# STM32MP21_CM33 register map
File version: 0.4
CPU: CM33 r0p1, little endian, MPU, FPU, vendor SysTick, 8 interrupt priority bits
Registers are 32-bit, read-write, reset 0x0 unless marked. A register's access mark holds for its fields unless they carry their own. Offsets are from the block's base; [hi:lo] are bit positions; {n}, {i} and the like mark numbered series; 'fields as' and 'values as' point back to an identical list.

## ETH1 (part 2 of 2) — ETH address block description
Base 0x482C0000
Same registers: ETH2 0x482D0000, ETH1_S 0x582C0000, ETH2_S 0x582D0000
0x7B8 ETH_RX_256TO511OCTETS_PACKETS_GOOD_BAD ro — Rx 256 to 511 octets packets good bad register
  [31:0] RX256_511OCTGB — Rx 256-511 Octets Packets Good Bad
0x7BC ETH_RX_512TO1023OCTETS_PACKETS_GOOD_BAD ro — Rx 512 to 1023 octets packets good bad register
  [31:0] RX512_1023OCTGB — Rx 512-1023 Octets Packets Good Bad
0x7C0 ETH_RX_1024TOMAXOCTETS_PACKETS_GOOD_BAD ro — Rx 1024 to max octets packets good bad register
  [31:0] RX1024_MAXOCTGB — Rx 1024-Max Octets Good Bad
0x7C4 ETH_RX_UNICAST_PACKETS_GOOD ro — Rx unicast packets good register
  [31:0] RXUCASTG — Rx Unicast Packets Good
0x7C8 ETH_RX_LENGTH_ERROR_PACKETS ro — Rx length error packets register
  [31:0] RXLENERR — Rx Length Error Packets
0x7CC ETH_RX_OUT_OF_RANGE_PACKETS ro — Rx out of range type packets register
  [31:0] RXOUTOFRNG — Rx Out of Range Type Packet
0x7D0 ETH_RX_PAUSE_PACKETS ro — Rx pause packets register
  [31:0] RXPAUSEPKT — Rx Pause Packets
0x7D4 ETH_RX_FIFO_OVERFLOW_PACKETS ro — Rx FIFO overflow packets register
  [31:0] RXFIFOOVFL — Rx FIFO Overflow Packets
0x7D8 ETH_RX_VLAN_PACKETS_GOOD_BAD ro — Rx VLAN packets good bad register
  [31:0] RXVLANPKTGB — Rx VLAN Packets Good Bad
0x7DC ETH_RX_WATCHDOG_ERROR_PACKETS ro — Rx watchdog error packets register
  [31:0] RXWDGERR — Rx Watchdog Error Packets
0x7E0 ETH_RX_RECEIVE_ERROR ro — Rx receive error register
  [31:0] RXRCVERR — Rx Receive Error Packets
0x7E4 ETH_RX_CONTROL_PACKETS_GOOD ro — Rx control packets good register
  [31:0] RXCTRLG — Rx Control Packets Good
0x7EC ETH_TX_LPI_USEC_CNTR ro — Tx LPI microsecond timer register
  [31:0] TXLPIUSC — Tx LPI Microseconds Counter
0x7F0 ETH_TX_LPI_TRAN_CNTR ro — Tx LPI transition counter register
  [31:0] TXLPITRC — Tx LPI Transition counter
0x7F4 ETH_RX_LPI_USEC_CNTR ro — Rx LPI microsecond counter register
  [31:0] RXLPIUSC — Rx LPI Microseconds Counter
0x7F8 ETH_RX_LPI_TRAN_CNTR ro — Rx LPI transition counter register
  [31:0] RXLPITRC — Rx LPI Transition counter
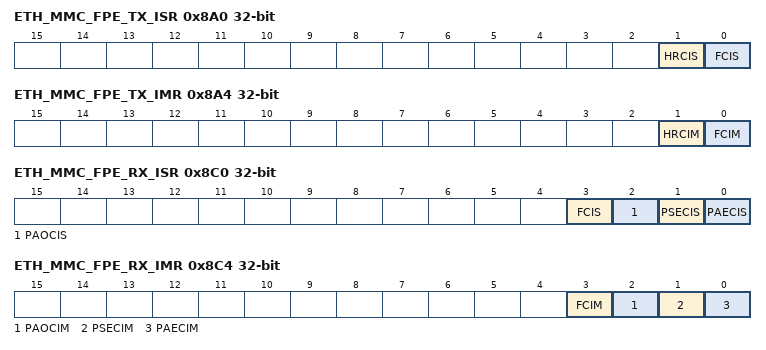
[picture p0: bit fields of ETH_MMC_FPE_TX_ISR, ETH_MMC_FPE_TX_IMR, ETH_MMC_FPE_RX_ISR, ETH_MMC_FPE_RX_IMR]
0x8A0 ETH_MMC_FPE_TX_ISR — MMC FPE Tx interrupt status register
  [1] HRCIS — MMC Tx Hold Request Counter Interrupt Status
  [0] FCIS — MMC Tx FPE Fragment Counter Interrupt status
0x8A4 ETH_MMC_FPE_TX_IMR — MMC FPE Tx interrupt mask register
  [1] HRCIM — MMC Transmit Hold Request Counter Interrupt Mask
  [0] FCIM — MMC Transmit Fragment Counter Interrupt Mask
0x8A8 ETH_MMC_FPE_TX_FCR ro — MMC FPE Tx fragment counter register
  [31:0] TXFFC — Tx FPE Fragment counter
0x8AC ETH_MMC_TX_HRCR ro — MMC Tx hold request counter register
  [31:0] TXHRC — Tx Hold Request Counter
0x8C0 ETH_MMC_FPE_RX_ISR ro — MMC FPE Rx interrupt status register
  [3] FCIS — MMC Rx FPE Fragment Counter Interrupt Status
  [2] PAOCIS — MMC Rx Packet Assembly OK Counter Interrupt Status
  [1] PSECIS — MMC Rx Packet SMD Error Counter Interrupt Status
  [0] PAECIS — MMC Rx Packet Assembly Error Counter Interrupt Status
0x8C4 ETH_MMC_FPE_RX_IMR — MMC FPE Rx interrupt mask register
  [3] FCIM — MMC Rx FPE Fragment Counter Interrupt Mask
  [2] PAOCIM — MMC Rx Packet Assembly OK Counter Interrupt Mask
  [1] PSECIM — MMC Rx Packet SMD Error Counter Interrupt Mask
  [0] PAECIM — MMC Rx Packet Assembly Error Counter Interrupt Mask
0x8C8 ETH_RX_PACKET_ASM_ERR ro — MMC Rx packet assembly error register
  [31:0] PAEC — Rx Packet Assembly Error Counter
0x8CC ETH_RX_PACKET_SMD_ERR ro — MMC Rx packet SMD error register
  [31:0] PSEC — Rx Packet SMD Error Counter
0x8D0 ETH_RX_PACKET_ASM_OKR ro — MMC Rx packet assembly OK register
  [31:0] PAOC — Rx Packet Assembly OK Counter
0x8D4 ETH_RX_FPE_FRAG_CR ro — MMC Rx FPE fragments counter register
  [31:0] FFC — Rx FPE Fragment Counter
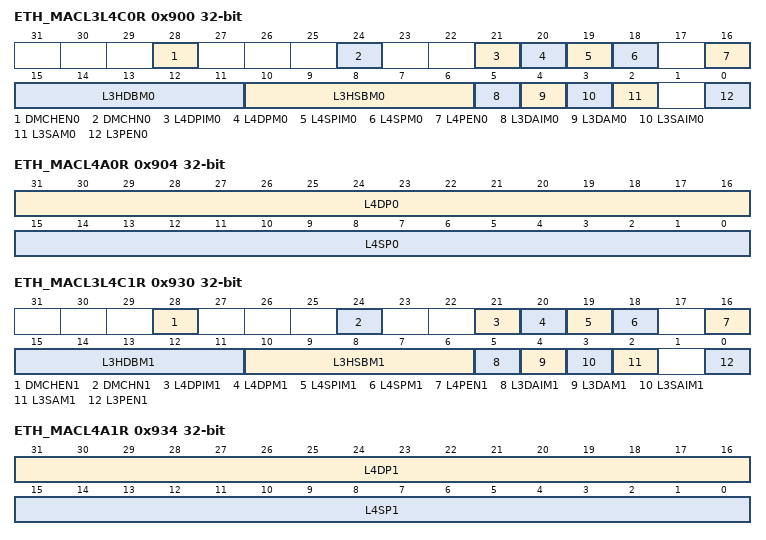
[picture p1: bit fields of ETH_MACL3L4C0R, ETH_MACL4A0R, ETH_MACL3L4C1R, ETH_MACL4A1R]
0x900 ETH_MACL3L4C0R — L3 and L4 control 0 register
  [28] DMCHEN0 — DMA Channel Select Enable
  [24] DMCHN0 — DMA Channel Number
    0=DMA channel 0; 1=DMA channel 1
  [21] L4DPIM0 — Layer 4 Destination Port Inverse Match Enable
  [20] L4DPM0 — Layer 4 Destination Port Match Enable
  [19] L4SPIM0 — Layer 4 Source Port Inverse Match Enable
  [18] L4SPM0 — Layer 4 Source Port Match Enable
  [16] L4PEN0 — Layer 4 Protocol Enable
  [15:11] L3HDBM0 — Layer 3 IP DA higher bits match
    0=B_0x0_IPV4_PACKETS (No bits are masked.); 1=B_0x1_IPV4_PACKETS (LSb[0] is masked)
  [10:6] L3HSBM0 — Layer 3 IP SA higher bits match
    values as L3HDBM0
  [5] L3DAIM0 — Layer 3 IP DA Inverse Match Enable
  [4] L3DAM0 — Layer 3 IP DA Match Enable
  [3] L3SAIM0 — Layer 3 IP SA Inverse Match Enable
  [2] L3SAM0 — Layer 3 IP SA Match Enable
  [0] L3PEN0 — Layer 3 Protocol Enable
0x904 ETH_MACL4A0R — Layer4 Address filter 0 register
  [31:16] L4DP0 — Layer 4 Destination Port Number Field
  [15:0] L4SP0 — Layer 4 Source Port Number Field
0x910 ETH_MACL3A00R — Layer3 Address 0 filter 0 register
  [31:0] L3A00 — Layer 3 Address 0 Field
0x914 ETH_MACL3A10R — Layer3 Address 1 filter 0 register
  [31:0] L3A10 — Layer 3 Address 1 Field
0x918 ETH_MACL3A20R — Layer3 Address 2 filter 0 register
  [31:0] L3A20 — Layer 3 Address 2 Field
0x91C ETH_MACL3A30R — Layer3 Address 3 filter 0 register
  [31:0] L3A30 — Layer 3 Address 3 Field
0x930 ETH_MACL3L4C1R — L3 and L4 control 1 register
  [28] DMCHEN1 — DMA Channel Select Enable
  [24] DMCHN1 — DMA Channel Number
  [21] L4DPIM1 — Layer 4 Destination Port Inverse Match Enable
  [20] L4DPM1 — Layer 4 Destination Port Match Enable
  [19] L4SPIM1 — Layer 4 Source Port Inverse Match Enable
  [18] L4SPM1 — Layer 4 Source Port Match Enable
  [16] L4PEN1 — Layer 4 Protocol Enable
  [15:11] L3HDBM1 — Layer 3 IP DA higher bits match
    values as ETH_MACL3L4C0R.L3HDBM0
  [10:6] L3HSBM1 — Layer 3 IP SA Higher Bits Match
    values as ETH_MACL3L4C0R.L3HDBM0
  [5] L3DAIM1 — Layer 3 IP DA Inverse Match Enable
  [4] L3DAM1 — Layer 3 IP DA Match Enable
  [3] L3SAIM1 — Layer 3 IP SA Inverse Match Enable
  [2] L3SAM1 — Layer 3 IP SA Match Enable
  [0] L3PEN1 — Layer 3 Protocol Enable
0x934 ETH_MACL4A1R — Layer 4 address filter 1 register
  [31:16] L4DP1 — Layer 4 Destination Port Number Field
  [15:0] L4SP1 — Layer 4 Source Port Number Field
0x940 ETH_MACL3A01R — Layer3 address 0 filter 1 Register
  [31:0] L3A01 — Layer 3 Address 0 Field
0x944 ETH_MACL3A11R — Layer3 address 1 filter 1 register
  [31:0] L3A11 — Layer 3 Address 1 Field
0x948 ETH_MACL3A21R — Layer3 address 2 filter 1 Register
  [31:0] L3A21 — Layer 3 Address 2 Field
0x94C ETH_MACL3A31R — Layer3 address 3 filter 1 register
  [31:0] L3A31 — Layer 3 Address 3 Field
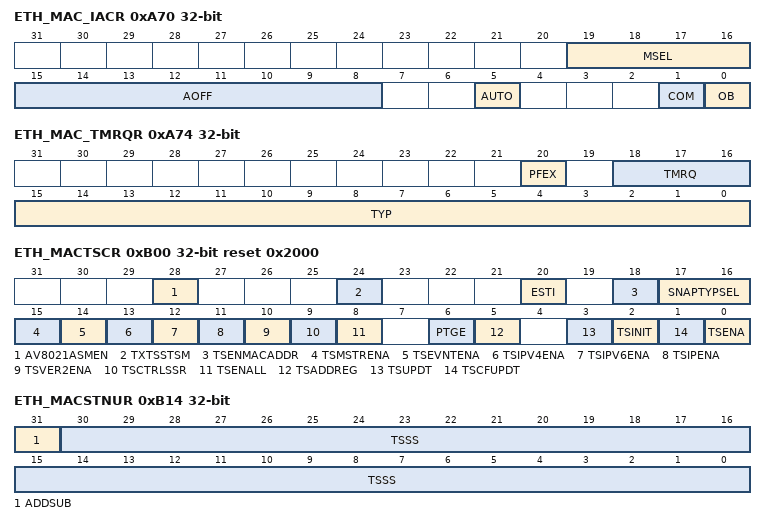
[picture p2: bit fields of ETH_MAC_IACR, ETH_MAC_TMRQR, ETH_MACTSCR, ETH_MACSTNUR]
0xA70 ETH_MAC_IACR — MAC Indirect Access Control register
  [19:16] MSEL — Mode Select
    0=Typ_RXQ_ (Type-based RXQ mapping)
  [15:8] AOFF — Address Offset
    0=IndReg0 (Indirect register 0); 1=IndReg1 (Indirect register 1); 7=IndReg7 (Indirect register 7)
  [5] AUTO — Auto-increment
    1=AOFF is incremented by 1; 0=AOFF is not automatically incremented
  [1] COM — Command type
    1=Indicates a read operation; 0=Indicates a write operation
  [0] OB — Operation Busy.
0xA74 ETH_MAC_TMRQR — MAC type-based Rx Queue mapping register
  [20] PFEX — Preemption or Express Packet
    0=Express packet; 1=Preemption packet
  [18:16] TMRQ — Type Match Rx Queue Number
  [15:0] TYP — Type field Value
0xB00 ETH_MACTSCR reset 0x2000 — Timestamp control Register
  [28] AV8021ASMEN — AV 802.
  [24] TXTSSTSM — Transmit Timestamp Status Mode
  [20] ESTI — External System Time Input
  [18] TSENMACADDR — Enable MAC Address for PTP Packet Filtering
  [17:16] SNAPTYPSEL — Select PTP packets for Taking Snapshots
  [15] TSMSTRENA — Enable Snapshot for Messages Relevant to Master
  [14] TSEVNTENA — Enable Timestamp Snapshot for Event Messages
  [13] TSIPV4ENA — Enable Processing of PTP Packets Sent over IPv4-UDP
  [12] TSIPV6ENA — Enable Processing of PTP Packets Sent over IPv6-UDP
  [11] TSIPENA — Enable Processing of PTP over Ethernet Packets
  [10] TSVER2ENA — Enable PTP Packet Processing for Version 2 Format
  [9] TSCTRLSSR — Timestamp Digital or Binary Rollover Control
  [8] TSENALL — Enable Timestamp for All Packets
  [6] PTGE — Presentation Time Generation Enable
  [5] TSADDREG — Update Addend Register
  [3] TSUPDT — Update Timestamp
  [2] TSINIT — Initialize Timestamp
  [1] TSCFUPDT — Fine or Coarse Timestamp Update
  [0] TSENA — Enable Timestamp
0xB04 ETH_MACSSIR — Subsecond increment register
  [23:16] SSINC — Subsecond Increment Value
0xB08 ETH_MACSTSR ro — System time seconds register
  [31:0] TSS — Timestamp Second
0xB0C ETH_MACSTNR ro — System time nanoseconds register
  [30:0] TSSS — Timestamp subseconds
0xB10 ETH_MACSTSUR — System time seconds update register
  [31:0] TSS — Timestamp Seconds
0xB14 ETH_MACSTNUR — System time nanoseconds update register
  [31] ADDSUB — Add or Subtract Time
  [30:0] TSSS — Timestamp subseconds
0xB18 ETH_MACTSAR — Timestamp addend register
  [31:0] TSAR — Timestamp Addend Register
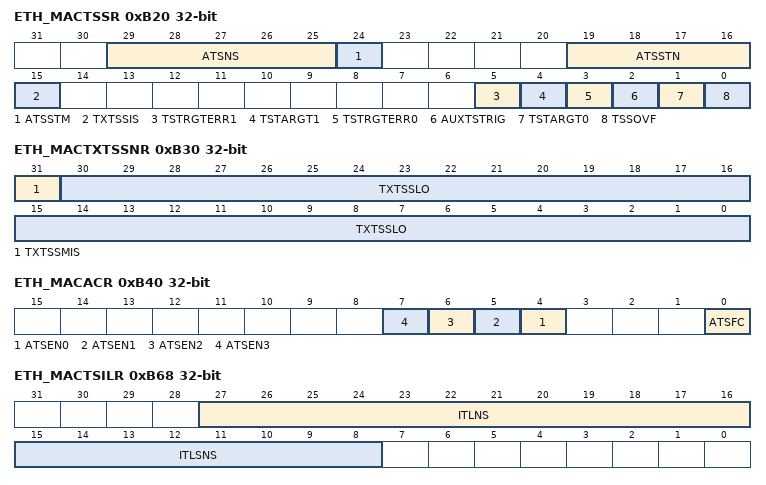
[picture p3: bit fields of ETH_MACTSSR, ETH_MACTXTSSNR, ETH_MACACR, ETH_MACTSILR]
0xB20 ETH_MACTSSR — Timestamp status register
  [29:25] ATSNS ro — Number of Auxiliary Timestamp Snapshots
  [24] ATSSTM — Auxiliary Timestamp Snapshot Trigger Missed
  [19:16] ATSSTN — Auxiliary Timestamp Snapshot Trigger Identifier
  [15] TXTSSIS — Tx Timestamp Status Interrupt Status
  [5] TSTRGTERR1 — Timestamp Target Time Error
  [4] TSTARGT1 — Timestamp Target Time Reached
  [3] TSTRGTERR0 — Timestamp Target Time Error
  [2] AUXTSTRIG — Auxiliary Timestamp Trigger Snapshot
  [1] TSTARGT0 — Timestamp Target Time Reached
  [0] TSSOVF — Timestamp Seconds Overflow
0xB24 ETH_MACRXDTI — Rx domain time increment register
  [31:16] RXNS — Receive domain time increment value in nanoseconds
0xB28 ETH_MACTXDTI — Tx domain time increment register
  [31:16] TXNS — Transmit domain time increment value in nanoseconds
0xB30 ETH_MACTXTSSNR — Tx timestamp status nanoseconds register
  [31] TXTSSMIS ro — Transmit Timestamp Status Missed
  [30:0] TXTSSLO — Transmit Timestamp Status Low
0xB34 ETH_MACTXTSSSR ro — Tx timestamp status seconds register
  [31:0] TXTSSHI — Transmit Timestamp Status High
0xB40 ETH_MACACR — Auxiliary control register
  [n+4] ATSEN{n} (n=0..3) — Auxiliary Snapshot {n} Enable
  [0] ATSFC — Auxiliary Snapshot FIFO Clear
0xB48 ETH_MACATSNR ro — Auxiliary timestamp nanoseconds register
  [30:0] AUXTSLO — Auxiliary Timestamp
0xB4C ETH_MACATSSR ro — Auxiliary timestamp seconds register
  [31:0] AUXTSHI — Auxiliary Timestamp
0xB50 ETH_MACTSIACR — Timestamp Ingress asymmetric correction register
  [31:0] OSTIAC — One-Step Timestamp Ingress Asymmetry Correction
0xB54 ETH_MACTSEACR — Timestamp Egress asymmetric correction register
  [31:0] OSTEAC — One-Step Timestamp Egress Asymmetry Correction
0xB58 ETH_MACTSICNR — Timestamp Ingress correction nanosecond register
  [31:0] TSIC — Timestamp Ingress Correction
0xB5C ETH_MACTSECNR — Timestamp Egress correction nanosecond register
  [31:0] TSEC — Timestamp Egress Correction
0xB68 ETH_MACTSILR ro — Timestamp Ingress Latency register
  [27:16] ITLNS — Ingress Timestamp Latency, in nanoseconds
  [15:8] ITLSNS — Ingress Timestamp Latency, in subnanoseconds
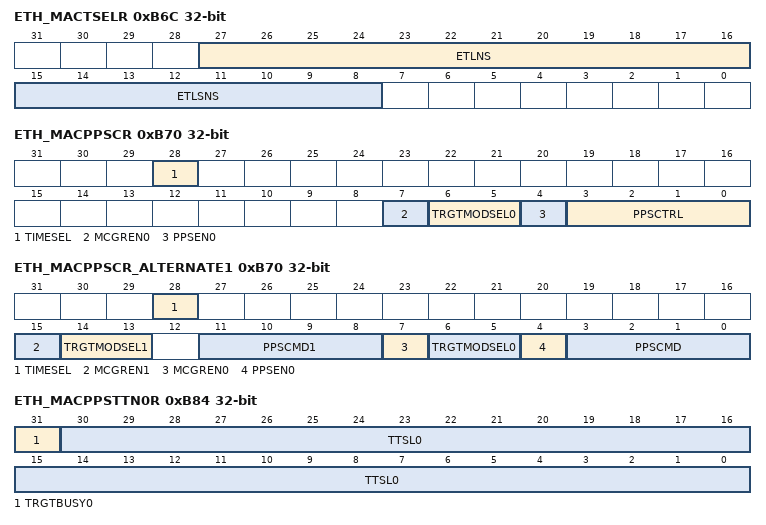
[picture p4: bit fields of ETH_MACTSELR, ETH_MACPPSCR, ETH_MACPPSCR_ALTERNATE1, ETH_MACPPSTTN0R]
0xB6C ETH_MACTSELR ro — Timestamp Egress Latency register
  [27:16] ETLNS — Egress Timestamp Latency, in nanoseconds
  [15:8] ETLSNS — Egress Timestamp Latency, in subnanoseconds
0xB70 ETH_MACPPSCR — PPS control register
  [28] TIMESEL — Time Select
  [7] MCGREN0 — MCGR Mode Enable for PPS0 Output
    0=PPS mode; 1=MCGR mode
  [6:5] TRGTMODSEL0 — Target Time Register Mode for PPS Output
    0=Target Time registers are programmed only for generating the interrupt event; 1=Enables MCGR Interrupt whose status bit is indicated by TSTARGT0 bit in Timestamp status register (ETH_MACTSSR) register; 2=Target Time registers are programmed for generating the interrupt event and starting or stopping the PPS output signal generation; 3=Target Time registers are programmed only for starting or stopping the PPS output signal generation
  [4] PPSEN0 — Flexible PPS Output Mode Enable
  [3:0] PPSCTRL — PPS Output Frequency Control
    1=The binary rollover is 2 Hz, and the digital rollover is 1 Hz; 2=The binary rollover is 4 Hz, and the digital rollover is 2 Hz; 3=The binary rollover is 8 Hz, and the digital rollover is 4 Hz; 4=The binary rollover is 16 Hz, and the digital rollover is 8 Hz; 15=The binary rollover is 32
0xB70 ETH_MACPPSCR_ALTERNATE1 (alternate view of ETH_MACPPSCR) — PPS control register
  [28] TIMESEL — Time Select
  [15] MCGREN1 — MCGR Mode Enable for PPS Output 1
    0=PPS mode; 1=MCGR mode
  [14:13] TRGTMODSEL1 — Target Time Register Mode for PPS Output 1
    0=Target time registers are programmed only for generating the interrupt event; 1=Enabled MCGR Interrupt whose status bit is indicated by TSTARGT1 bit in Timestamp status register (ETH_MACTSSR) register; 2=Target time registers are programmed for generating the interrupt event and starting or stopping the PPS output signal generation; 3=Target time registers are programmed only for starting or stopping the PPS output signal generation
  [11:8] PPSCMD1 — Flexible PPS Output 1 Control
  [7] MCGREN0 — MCGR Mode Enable for PPS Output 0
    0=PPS mode; 1=MCGR mode
  [6:5] TRGTMODSEL0 — Target Time Register Mode for PPS Output 0
    0=Target Time registers are programmed only for generating the interrupt event; 1=Enables MCGR Interrupt whose status bit is indicated by TSTARGT0 bit in Timestamp status register (ETH_MACTSSR) register; 2=Target Time registers are programmed for generating the interrupt event and starting or stopping the PPS output 0 signal generation; 3=Target Time registers are programmed only for starting or stopping the PPS output 0 signal generation
  [4] PPSEN0 — Flexible PPS Output 0 Mode Enable
  [3:0] PPSCMD — Flexible PPS Output 0 (eth_ptp_pps_out) Control
    0=No Command; 1=START Single Pulse; 2=START Pulse Train; 3=Cancel START; 4=STOP Pulse Train at time; 5=STOP Pulse Train immediately; 6=Cancel STOP Pulse train
0xB80 ETH_MACPPSTTS0R — PPS 0 target time seconds register
  [31:0] TSTRH0 — PPS Target Time Seconds Register
0xB84 ETH_MACPPSTTN0R — PPS 0 target time nanoseconds register
  [31] TRGTBUSY0 — PPS Target Time Register Busy
  [30:0] TTSL0 — Target Time Low for PPS Register
0xB88 ETH_MACPPSI0R — PPS 0 interval register
  [31:0] PPSINT0 — PPS Output Signal Interval
0xB8C ETH_MACPPSW0R — PPS 0 width register
  [31:0] PPSWIDTH0 — PPS Output Signal Width
0xB90 ETH_MACPPSTTS1R — PPS 1 target time seconds register
  [31:0] TSTRH0 — PPS Target Time Seconds Register
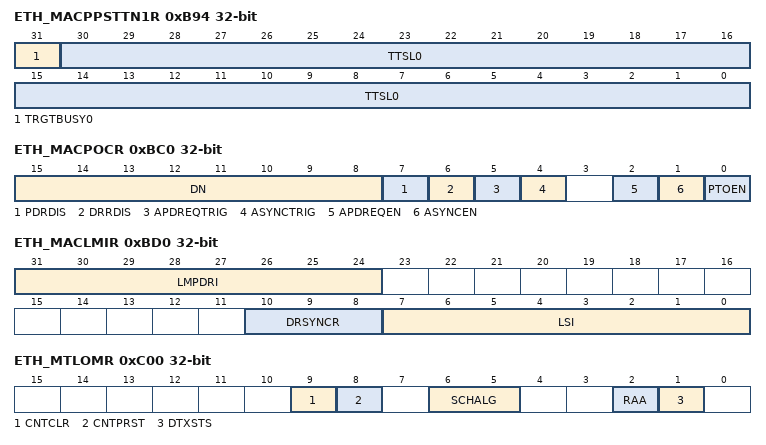
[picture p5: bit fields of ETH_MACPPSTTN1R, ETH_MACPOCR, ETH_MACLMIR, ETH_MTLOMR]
0xB94 ETH_MACPPSTTN1R — PPS 1 target time nanoseconds register
  fields as ETH_MACPPSTTN0R
0xB98 ETH_MACPPSI1R — PPS 1 interval register
  [31:0] PPSINT0 — PPS Output Signal Interval
0xB9C ETH_MACPPSW1R — PPS 1 width register
  [31:0] PPSWIDTH0 — PPS Output Signal Width
0xBC0 ETH_MACPOCR — PTP Offload control register
  [15:8] DN — Domain Number
  [7] PDRDIS — Disable Peer Delay Response response generation
  [6] DRRDIS — Disable PTO Delay Request/Response response generation
  [5] APDREQTRIG — Automatic PTP Pdelay_Req message Trigger
  [4] ASYNCTRIG — Automatic PTP SYNC message Trigger
  [2] APDREQEN — Automatic PTP Pdelay_Req message Enable
  [1] ASYNCEN — Automatic PTP SYNC message Enable
  [0] PTOEN — PTP Offload Enable
0xBC4 ETH_MACSPI0R — PTP Source Port Identity 0 Register
  [31:0] SPI0 — Source Port Identity 0
0xBC8 ETH_MACSPI1R — PTP Source port identity 1 register
  [31:0] SPI1 — Source Port Identity 1
0xBCC ETH_MACSPI2R — PTP Source port identity 2 register
  [15:0] SPI2 — Source Port Identity 2
0xBD0 ETH_MACLMIR — Log message interval register
  [31:24] LMPDRI — Log Min Pdelay_Req Interval
  [10:8] DRSYNCR — Delay_Req to SYNC Ratio
    0=DelayReq generated for every received SYNC; 1=DelayReq generated every alternate reception of SYNC
  [7:0] LSI — Log Sync Interval
0xC00 ETH_MTLOMR — Operating mode register
  [9] CNTCLR — Counters Reset
  [8] CNTPRST — Counters Preset
  [6:5] SCHALG — Tx Scheduling Algorithm
    0=Weighted round robin (WRR) algorithm; 3=Strict priority (SP) algorithm
  [2] RAA — Receive Arbitration Algorithm
    0=Strict priority (SP); 1=Weighted Strict priority (WSP)
  [1] DTXSTS — Drop Transmit Status
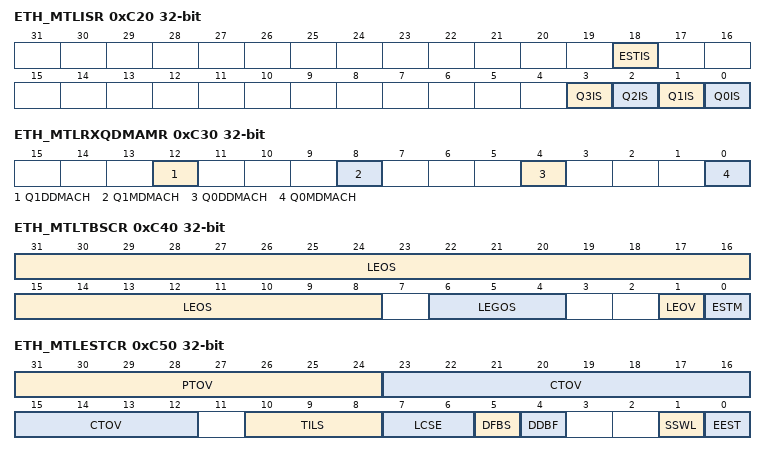
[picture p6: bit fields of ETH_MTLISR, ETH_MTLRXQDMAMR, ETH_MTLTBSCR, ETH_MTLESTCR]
0xC20 ETH_MTLISR ro — Interrupt status register
  [18] ESTIS — EST (TAS- 802.
  [n] Q{n}IS (n=0..3) — Queue {n} interrupt status
0xC30 ETH_MTLRXQDMAMR — Rx Queue and DMA Channel Mapping register
  [12] Q1DDMACH — Queue 1 Enabled for DA-based DMA Channel Selection
  [8] Q1MDMACH — Queue 1 Mapped to DMA Channel
    0=DMA Channel 0; 1=DMA Channel 1
  [4] Q0DDMACH — Queue 0 Enabled for DA-based DMA Channel Selection
  [0] Q0MDMACH — Queue 0 Mapped to DMA Channel
    0=DMA Channel 0; 1=DMA Channel 1
0xC40 ETH_MTLTBSCR — TBS control register
  [31:8] LEOS — Launch Expiry Offset
  [6:4] LEGOS — Launch Expiry GSN Offset
  [1] LEOV — Launch expiry offset valid
    0=LEOS field invalid; 1=LEOS field valid
  [0] ESTM — EST offset mode
    0=EST offset mode disabled; 1=EST offset mode enabled
0xC50 ETH_MTLESTCR — EST Control register
  [31:24] PTOV — PTP Time Offset Value
  [23:12] CTOV — Current Time Offset Value
  [10:8] TILS — Time Interval Left Shift Amount
    0=No left shift needed (equal to x1ns); 1=Left shift TI by 1 bit (equal to x2ns); 2=Left shift TI by 2 bits (equal to x4ns); 4=Left shift TI by 7 bits (equal to x128ns)
  [7:6] LCSE — Loop Count to report Scheduling Error
    0=4 iterations; 1=8 iterations; 2=16 iterations; 3=32 iterations
  [5] DFBS — Drop Frames causing Scheduling Error
    0=Do not drop; 1=Drop
  [4] DDBF — Do not Drop frames during Frame Size Error
    0=Drop; 1=Do not drop
  [1] SSWL — Switch to S/W owned list
  [0] EEST — Enable EST
    0=EST disabled; 1=EST enabled
0xC54 ETH_MTLESTECR — EST Extended Control register
  [5:0] OVHD — Overhead Bytes Value
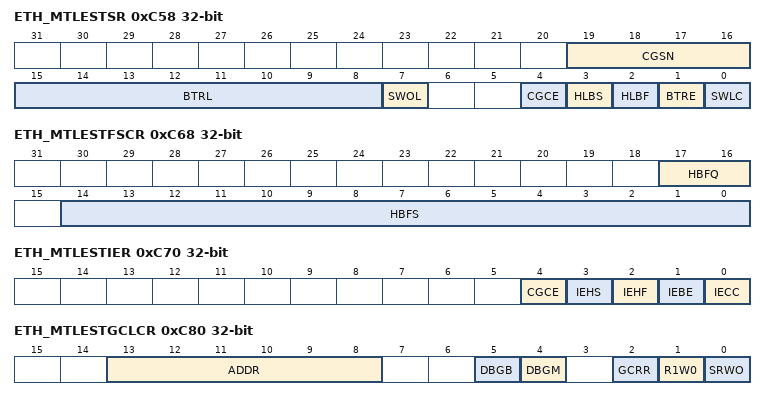
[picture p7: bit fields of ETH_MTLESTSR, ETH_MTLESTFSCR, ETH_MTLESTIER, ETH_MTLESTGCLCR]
0xC58 ETH_MTLESTSR — EST Status register
  [19:16] CGSN ro — Current GCL slot number
  [15:8] BTRL ro — BTR Error Loop Count
  [7] SWOL ro — S/W owned list
    0=Inactive; 1=Active
  [4] CGCE — Constant Gate Control Error
    0=Inactive; 1=Active
  [3] HLBS ro — Head-Of-Line Blocking due to Scheduling
    0=Inactive; 1=Active
  [2] HLBF ro — Head-Of-Line Blocking due to Frame Size
  [1] BTRE — BTR Error
    0=Inactive; 1=Active
  [0] SWLC — Switch to S/W owned list Complete
    0=Inactive; 1=Active
0xC60 ETH_MTLESTSCHER — EST Schedule Error register
  [3:0] SEQN — Schedule Error Queue Number
0xC64 ETH_MTLESTFSER — EST Frame size Error register
  [3:0] FEQN — Frame Size Error Queue Number
0xC68 ETH_MTLESTFSCR ro — EST Frame size Capture register
  [17:16] HBFQ — Queue Number of HLBF
  [14:0] HBFS — Frame Size of HLBF
0xC70 ETH_MTLESTIER — EST Interrupt Enable register
  [4] CGCE — Interrupt Enable for CGCE
  [3] IEHS — Interrupt Enable for HLBS
  [2] IEHF — Interrupt Enable for HLBF
  [1] IEBE — Interrupt Enable for BTR Error
  [0] IECC — Interrupt Enable for Switch List
0xC80 ETH_MTLESTGCLCR — EST Gate Control List register
  [13:8] ADDR — Gate Control List Address:
    0=B_0x0_GCRR__EQUAL_1 (BTR Low (31:0)); 1=B_0x1_GCRR__EQUAL_1 (BTR High (63:31)); 2=B_0x2_GCRR__EQUAL_1 (CTR Low (31:0)); 3=B_0x3_GCRR__EQUAL_1 (CTR High (39:32)); 4=B_0x4_GCRR__EQUAL_1 (TER (30:0)); 5=B_0x5_GCRR__EQUAL_1 (LLR (6:0))
  [5] DBGB — Debug Mode Bank Select
    0=Bank 0; 1=Bank 1
  [4] DBGM — Debug Mode
  [2] GCRR — Gate Control Related registers
  [1] R1W0 — Read 1, Write 0
    1=Read operation; 0=Write operation
  [0] SRWO — Start Read/Write Operation
    1=Indicates the start/progress of a Read/Write operation
0xC84 ETH_MTLESTGCLDR — EST Gate Control List Data register
  [31:0] GCD — Gate Control Data
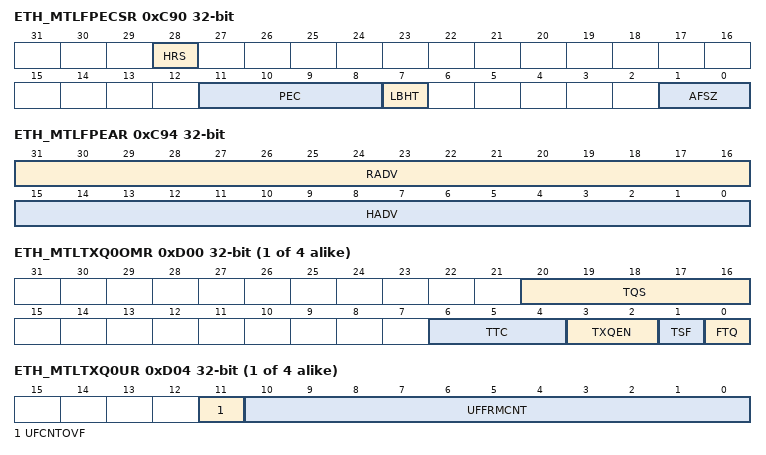
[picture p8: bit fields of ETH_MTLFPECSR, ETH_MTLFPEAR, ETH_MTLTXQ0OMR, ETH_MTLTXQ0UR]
0xC90 ETH_MTLFPECSR — FPE Frame Preemption Control Status register
  [28] HRS — Hold/Release Status
    1=Indicates a Set-and-Hold-MAC operation was last executed and the pMAC is in Hold State; 0=Indicates a Set-and-Release-MAC operation was last executed and the pMAC is in Release State
  [11:8] PEC — Preemption Classification
  [7] LBHT — Level-based Hold Transition
  [1:0] AFSZ — Additional Fragment Size
0xC94 ETH_MTLFPEAR — FPE Frame Preemption Advance register
  [31:16] RADV — Release Advance
  [15:0] HADV — Hold Advance
{0xD00+0x40*i} ETH_MTLTXQ{i}OMR (i=0..3) — T{i} queue {i} operating mode register
  [20:16] TQS — Transmit queue size
  [6:4] TTC — Transmit Threshold Control
    0=32; 1=64; 2=96; 3=128; 4=192; 5=256; 6=384; 7=512
  [3:2] TXQEN — Transmit Queue Enable
    0=Not enabled; 1=Enable in AV mode; 2=Enabled
  [1] TSF — Transmit Store and Forward
  [0] FTQ — Flush Transmit Queue
{0xD04+0x40*i} ETH_MTLTXQ{i}UR (i=0..3) — T{i} queue {i} underflow register
  [11] UFCNTOVF — Overflow Bit for Underflow Packet Counter
  [10:0] UFFRMCNT — Underflow Packet Counter
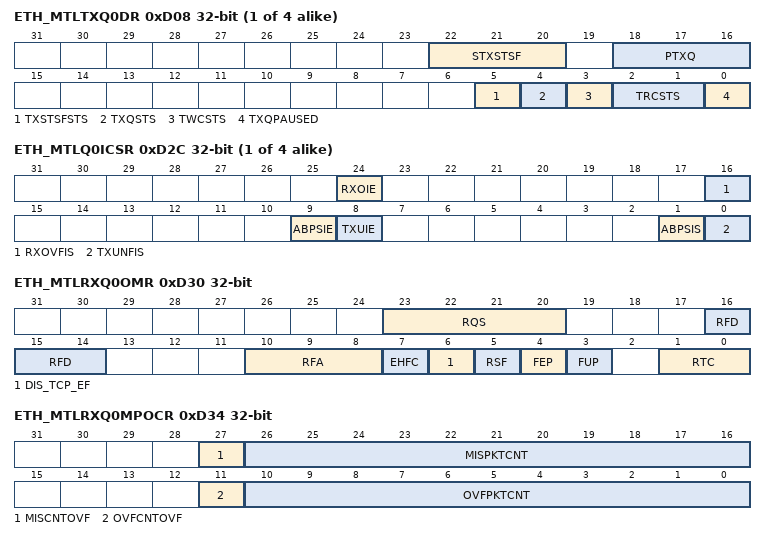
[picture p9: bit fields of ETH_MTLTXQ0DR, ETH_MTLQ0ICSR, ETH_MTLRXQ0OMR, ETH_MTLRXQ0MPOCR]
{0xD08+0x40*i} ETH_MTLTXQ{i}DR ro (i=0..3) — T{i} queue {i} debug register
  [22:20] STXSTSF — Number of Status Words in Tx Status FIFO of Queue
  [18:16] PTXQ — Number of Packets in the Transmit Queue
  [5] TXSTSFSTS — MTL Tx Status FIFO Full Status
  [4] TXQSTS — MTL Tx Queue Not Empty Status
  [3] TWCSTS — MTL Tx Queue Write Controller Status
  [2:1] TRCSTS — MTL Tx Queue Read Controller Status
    0=Idle state; 1=Read state (transferring data to the MAC transmitter); 2=Waiting for pending Tx Status from the MAC transmitter; 3=Flushing the Tx queue because of the Packet Abort request from the MAC
  [0] TXQPAUSED — Transmit Queue in Pause
{0xD14+0x40*i} ETH_MTLTXQ{i}ESR ro (i=0..3) — T{i} queue {i} ETS status register
  [23:0] ABS — Average Bits per Slot
{0xD18+0x40*i} ETH_MTLTXQ{i}QWR (i=0..3) — T{i} queue {i} quantum weight register
  [13:0] ISCQW — IdleSlopeCredit or Weights
{0xD2C+0x40*i} ETH_MTLQ{i}ICSR (i=0..3) — Queue {i} interrupt control status register
  [24] RXOIE — Receive Queue Overflow Interrupt Enable
  [16] RXOVFIS — Receive Queue Overflow Interrupt Status
  [9] ABPSIE — Average Bits Per Slot Interrupt Enable
  [8] TXUIE — Transmit Queue Underflow Interrupt Enable
  [1] ABPSIS — Average Bits Per Slot Interrupt Status
  [0] TXUNFIS — Transmit Queue Underflow Interrupt Status
0xD30 ETH_MTLRXQ0OMR — R0 queue 0 operating mode register
  [23:20] RQS — Receive Queue Size
  [16:14] RFD — Threshold for Deactivating Flow Control (in Half-duplex and Full-duplex modes)
    0=Full minus 1 Kbyte; 1=Full minus 1
  [10:8] RFA — Threshold for Activating Flow Control (in Half-duplex and Full-duplex)
  [7] EHFC — Enable Hardware Flow Control
  [6] DIS_TCP_EF — Disable Dropping of TCP/IP Checksum Error Packets
  [5] RSF — Receive Queue Store and Forward
  [4] FEP — Forward Error Packets
  [3] FUP — Forward Undersized Good Packets
  [1:0] RTC — Receive Queue Threshold Control
    0=64; 1=32; 2=96; 3=128
0xD34 ETH_MTLRXQ0MPOCR — R0 queue 0 missed packet and overflow counter register
  [27] MISCNTOVF — Missed Packet Counter Overflow Bit
  [26:16] MISPKTCNT — Missed Packet Counter
  [11] OVFCNTOVF — Overflow Counter Overflow Bit
  [10:0] OVFPKTCNT — Overflow Packet Counter
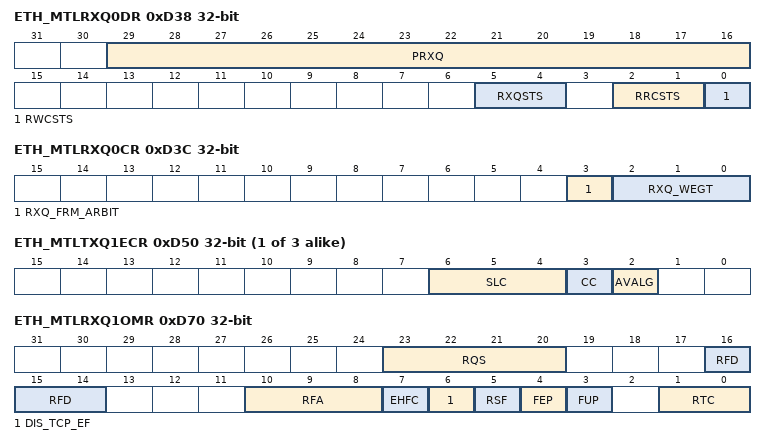
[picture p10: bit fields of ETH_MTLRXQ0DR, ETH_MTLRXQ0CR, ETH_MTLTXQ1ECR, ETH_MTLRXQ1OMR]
0xD38 ETH_MTLRXQ0DR ro — R0 queue 0 debug register
  [29:16] PRXQ — Number of Packets in Receive Queue
  [5:4] RXQSTS — MTL Rx Queue Fill-Level Status
    0=Rx queue empty; 1=Rx queue fill-level below flow-control deactivate threshold; 2=Rx queue fill-level above flow-control activate threshold; 3=Rx queue full
  [2:1] RRCSTS — MTL Rx Queue Read Controller State
    0=Idle state; 1=Reading packet data; 2=Reading packet status (or timestamp); 3=Flushing the packet data and status
  [0] RWCSTS — MTL Rx Queue Write Controller Active Status
0xD3C ETH_MTLRXQ0CR — R0 queue 0 control register
  [3] RXQ_FRM_ARBIT — Receive Queue Packet Arbitration
  [2:0] RXQ_WEGT — Receive Queue Weight
{0xD10+0x40*i} ETH_MTLTXQ{i}ECR (i=1..3) — T{i} queue {i} ETS control register
  [6:4] SLC — Slot Count
    0=1 Slot; 1=2 Slots; 2=4 Slots; 3=8 Slots; 4=16 Slots
  [3] CC — Credit Control
  [2] AVALG — AV Algorithm
{0xD1C+0x40*i} ETH_MTLTXQ{i}SSCR (i=1..3) — T{i} queue {i} send slope credit register
  [13:0] SSC — sendSlopeCredit Value
{0xD20+0x40*i} ETH_MTLTXQ{i}HCR (i=1..3) — T{i} Queue {i} hiCredit register
  [28:0] HC — hiCredit Value
{0xD24+0x40*i} ETH_MTLTXQ{i}LCR (i=1..3) — T{i} queue {i} loCredit register
  [28:0] LC — loCredit Value
0xD70 ETH_MTLRXQ1OMR — R1 queue 1 operating mode register
  fields as ETH_MTLRXQ0OMR
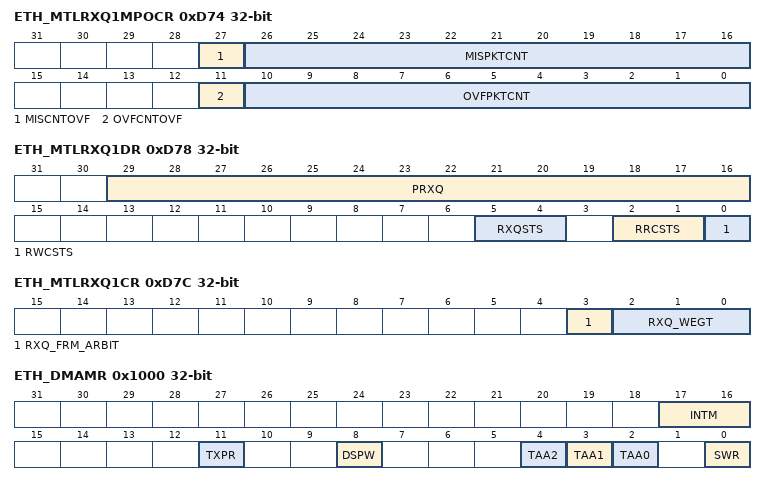
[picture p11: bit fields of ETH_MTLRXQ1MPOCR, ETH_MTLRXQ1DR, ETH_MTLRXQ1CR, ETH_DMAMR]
0xD74 ETH_MTLRXQ1MPOCR — R1 queue 1 missed packet and overflow counter register
  fields as ETH_MTLRXQ0MPOCR
0xD78 ETH_MTLRXQ1DR ro — R1 queue 1 debug register
  fields as ETH_MTLRXQ0DR
0xD7C ETH_MTLRXQ1CR — R1 queue 1 control register
  fields as ETH_MTLRXQ0CR
0x1000 ETH_DMAMR — DMA mode register
  [17:16] INTM — Interrupt Mode
  [11] TXPR — Transmit priority
  [8] DSPW — Descriptor Posted Write
    0=The descriptor writes are always non-posted; 1=The descriptor writes are non-posted only when IOC (Interrupt on completion) is set in last descriptor
  [4] TAA2 ro — Transmit Arbitration Algorithm
    0=Fixed priority; 1=Weighted Strict priority (WSP)
  [3] TAA1 ro — Transmit Arbitration Algorithm
    0=Fixed priority; 1=Weighted Strict priority (WSP)
  [2] TAA0 ro — Transmit Arbitration Algorithm
    0=Fixed priority; 1=Weighted Strict priority (WSP)
  [0] SWR — Software Reset
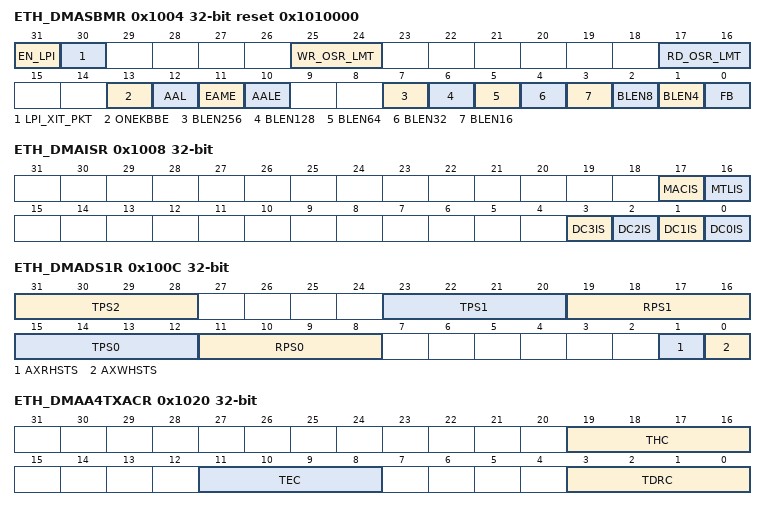
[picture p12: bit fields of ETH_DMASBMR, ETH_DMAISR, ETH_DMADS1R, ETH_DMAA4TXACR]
0x1004 ETH_DMASBMR reset 0x1010000 — System bus mode register
  [31] EN_LPI — Enable Low Power Interface (LPI)
  [30] LPI_XIT_PKT — Unlock on Magic Packet or Remote wake-up Packet
  [25:24] WR_OSR_LMT — AXI Maximum Write Outstanding Request Limit
  [17:16] RD_OSR_LMT — AXI Maximum Read Outstanding Request Limit
  [13] ONEKBBE — 1 Kbyte Boundary Crossing Enable for the AXI Master
  [12] AAL — Address-Aligned Beats
  [11] EAME — Enhanced Address Mode Enable
  [10] AALE — Automatic AXI LPI enable
  [7] BLEN256 — AXI Burst Length 256
  [6] BLEN128 — AXI Burst Length 128
  [5] BLEN64 — AXI Burst Length 64
  [4] BLEN32 — AXI Burst Length 32
  [3] BLEN16 — AXI Burst Length 16
  [2] BLEN8 — AXI Burst Length 8
  [1] BLEN4 — AXI Burst Length 4
  [0] FB — Fixed Burst Length
0x1008 ETH_DMAISR ro — Interrupt status register
  [17] MACIS — MAC Interrupt Status
  [16] MTLIS — MTL Interrupt Status
  [3] DC3IS — DMA Channel 3 Interrupt Status
  [2] DC2IS — DMA Channel 2 Interrupt Status
  [1] DC1IS — DMA Channel 1 Interrupt Status
  [0] DC0IS — DMA Channel Interrupt Status
0x100C ETH_DMADS1R ro — Debug status 1 register
  [31:28] TPS2 — DMA Channel 2 Transmit Process State
  [23:20] TPS1 — DMA Channel 1 Transmit Process State
  [19:16] RPS1 — DMA Channel 1 Receive Process State
  [15:12] TPS0 — DMA Channel Transmit Process State
    0=Stopped (Reset or Stop Transmit Command issued); 1=Running (Fetching Tx Transfer Descriptor); 2=Running (Waiting for status); 3=Running (Reading Data from system memory buffer and queuing it to the Tx buffer (Tx FIFO)); 4=Timestamp write state; 6=Suspended (Tx Descriptor Unavailable or Tx Buffer Underflow); 7=Running (Closing Tx Descriptor)
  [11:8] RPS0 — DMA Channel Receive Process State
    0=Stopped (Reset or Stop Receive Command issued); 1=Running (Fetching Rx Transfer Descriptor); 3=Running (Waiting for Rx packet); 4=Suspended (Rx Descriptor Unavailable); 5=Running (Closing the Rx Descriptor); 6=Timestamp write state; 7=Running (Transferring the received packet data from the Rx buffer to the system memory)
  [1] AXRHSTS — AXI Master Read Channel Status
  [0] AXWHSTS — AXI Master Write Channel
0x1010 ETH_DMADS2R ro — Debug status 2 register
  [7:4] TPS3 — DMA Channel 3 Transmit Process State
0x1020 ETH_DMAA4TXACR — AXI4 transmit channel ACE control register
  [19:16] THC — Transmit DMA First Packet Buffer or TSO Header Cache Control
  [11:8] TEC — Transmit DMA Extended Packet Buffer or TSO Payload Cache Control
  [3:0] TDRC — Transmit DMA Read Descriptor Cache Control
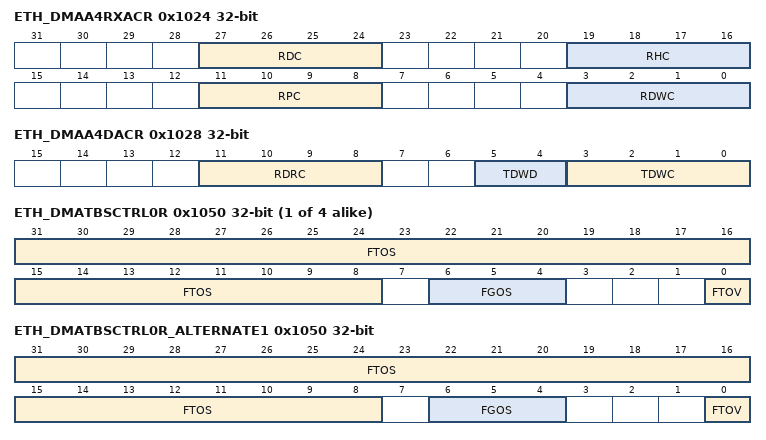
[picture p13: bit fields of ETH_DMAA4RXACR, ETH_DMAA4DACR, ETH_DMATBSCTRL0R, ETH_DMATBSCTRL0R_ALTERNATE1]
0x1024 ETH_DMAA4RXACR — AXI4 receive channel ACE control register
  [27:24] RDC — Receive DMA Buffer Cache Control
  [19:16] RHC — Receive DMA Header Cache Control
  [11:8] RPC — Receive DMA Payload Cache Control
  [3:0] RDWC — Receive DMA Write Descriptor Cache Control
0x1028 ETH_DMAA4DACR — AXI4 descriptor ACE control register
  [11:8] RDRC — Receive DMA Read Descriptor Cache control
  [5:4] TDWD — Transmit DMA Write Descriptor Domain control
  [3:0] TDWC — Transmit DMA Write Descriptor Cache control
0x1040 ETH_DMALPIEI — AXI4 LPI Entry Interval register
  [3:0] LPIEI — LPI Entry Interval
{0x1050+4i} ETH_DMATBSCTRL{i}R (i=0..3) — DMA TBS control register {i}
  [31:8] FTOS — Fetch time offset
  [6:4] FGOS — Fetch GSN offset
  [0] FTOV — Fetch time offset valid
    0=Fetch time offset invalid; 1=Fetch time offset valid
0x1050 ETH_DMATBSCTRL0R_ALTERNATE1 (alternate view of ETH_DMATBSCTRL0R) — DMA TBS control register 0
  fields as ETH_DMATBSCTRL0R
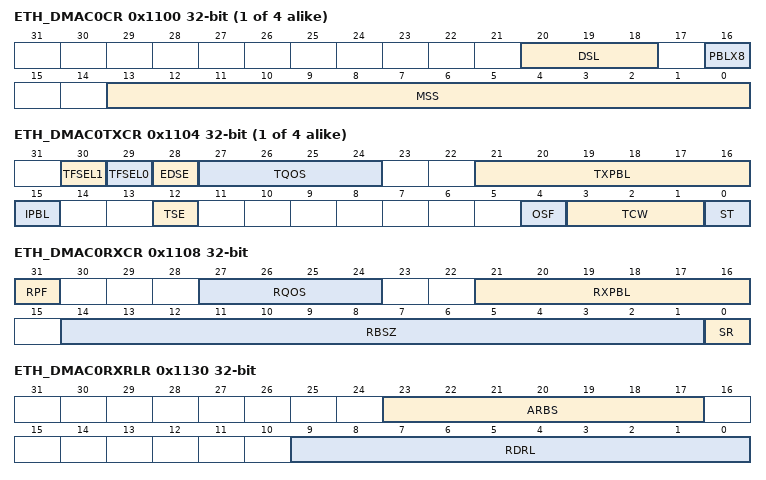
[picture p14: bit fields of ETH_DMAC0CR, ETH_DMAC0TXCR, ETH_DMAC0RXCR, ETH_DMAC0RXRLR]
{0x1100+0x80*i} ETH_DMAC{i}CR (i=0..3) — Channel {i} control register
  [20:18] DSL — Descriptor Skip Length
  [16] PBLX8 — 8xPBL mode
  [13:0] MSS — Maximum Segment Size
{0x1104+0x80*i} ETH_DMAC{i}TXCR (i=0..3) — Channel {i} transmit control register
  [30] TFSEL1 — TBS Fetch Select
    0=ETH_DMATBSCTRL0R; 1=ETH_DMATBSCTRL1R
  [29] TFSEL0 — TBS Fetch Select
    0=ETH_DMATBSCTRL0R; 1=ETH_DMATBSCTRL1R
  [28] EDSE — Enhanced Descriptor Enable
  [27:24] TQOS — Transmit QOS
  [21:16] TXPBL — Transmit Programmable Burst Length
  [15] IPBL — Ignore PBL Requirement
  [12] TSE — TCP Segmentation Enabled
  [4] OSF — Operate on Second Packet
  [3:1] TCW ro — Transmit Channel Weight
  [0] ST — Start or Stop Transmission Command
0x1108 ETH_DMAC0RXCR — Channel 0 receive control register
  [31] RPF — DMA Rx Channel x Packet Flush
  [27:24] RQOS — Rx AXI4 QOS.
  [21:16] RXPBL — Receive Programmable Burst Length
  [14:1] RBSZ — Receive Buffer size
  [0] SR — Start or Stop Receive
{0x1110+0x80*i} ETH_DMAC{i}TXDLHAR (i=0..3) — Channel {i} T{i} descriptor list high address register
  [7:0] TDESHA — Start of Transmit List
{0x1114+0x80*i} ETH_DMAC{i}TXDLAR (i=0..3) — Channel {i} T{i} descriptor list address register
  [31:0] TDESLA — Start of Transmit List
0x1118 ETH_DMAC0RXDLHAR — Channel 0 R0 descriptor list high address register
  [7:0] RDESHA — Start of Receive List
0x111C ETH_DMAC0RXDLAR — Channel 0 R0 descriptor list address register
  [31:0] RDESLA — Start of Receive List
{0x1120+0x80*i} ETH_DMAC{i}TXDTPR (i=0..3) — Channel {i} T{i} descriptor tail pointer register
  [31:0] TDT — Transmit Descriptor Tail Pointer
0x1128 ETH_DMAC0RXDTPR — Channel 0 R0 descriptor tail pointer register
  [31:0] RDT — Receive Descriptor Tail Pointer
{0x112C+0x80*i} ETH_DMAC{i}TXRLR (i=0..3) — Channel {i} T{i} descriptor ring length register
  [9:0] TDRL — Transmit Descriptor Ring Length
0x1130 ETH_DMAC0RXRLR — Channel 0 R0 descriptor ring length register
  [23:17] ARBS — Alternate Receive Buffer Size
  [9:0] RDRL — Receive Descriptor Ring Length
{0x1134+0x80*i} ETH_DMAC{i}IER (i=0..3) — Channel {i} interrupt enable register
  [15] NIE — Normal Interrupt Summary Enable
  [14] AIE — Abnormal Interrupt Summary Enable
  [13] CDEE — Context Descriptor Error Enable
  [12] FBEE — Fatal Bus Error Enable
  [11] ERIE — Early Receive Interrupt Enable
  [10] ETIE — Early Transmit Interrupt Enable
  [9] RWTE — Receive Watchdog Timeout Enable
  [8] RSE — Receive Stopped Enable
  [7] RBUE — Receive Buffer Unavailable Enable
  [6] RIE — Receive Interrupt Enable
  [2] TBUE — Transmit Buffer Unavailable Enable
  [1] TXSE — Transmit Stopped Enable
  [0] TIE — Transmit Interrupt Enable
0x1138 ETH_DMAC0RXIWTR — Channel 0 R0 interrupt watchdog timer register
  [17:16] RWTU — Receive Interrupt Watchdog Timer Count Units
    0=256; 1=512; 2=1024; 3=2048
  [7:0] RWT — Receive Interrupt Watchdog Timer Count
{0x113C+0x80*i} ETH_DMAC{i}SFCSR reset 0x7C0 (i=0..3) — Channel {i} slot function control status register
  [19:16] RSN ro — Reference Slot Number
  [15:4] SIV — Slot Interval Value
  [1] ASC — Advance Slot Check
  [0] ESC — Enable Slot Comparison
{0x1144+0x80*i} ETH_DMAC{i}CATXDR ro (i=0..3) — Channel {i} current application transmit descriptor register
  [31:0] CURTDESAPTR — Application Transmit Descriptor Address Pointer
0x114C ETH_DMAC0CARXDR ro — Channel 0 current application receive descriptor register
  [31:0] CURRDESAPTR — Application Receive Descriptor Address Pointer
{0x1150+0x80*i} ETH_DMAC{i}CATXBHR ro (i=0..3) — Channel {i} current application transmit buffer high register
  [7:0] CURTBUFAPTRH — Application Transmit Buffer Address Pointer
{0x1154+0x80*i} ETH_DMAC{i}CATXBR ro (i=0..3) — Channel {i} current application transmit buffer register
  [31:0] CURTBUFAPTR — Application Transmit Buffer Address Pointer
0x1158 ETH_DMAC0CARXBHR ro — Channel 0 current application receive buffer high register
  [7:0] CURRBUFAPTRH — Application Receive Buffer Address Pointer
0x115C ETH_DMAC0CARXBR ro — Channel 0 current application receive buffer register
  [31:0] CURRBUFAPTR — Application Receive Buffer Address Pointer
{0x1160+0x80*i} ETH_DMAC{i}SR (i=0..3) — Channel {i} status register
  [21:19] REB ro — Rx DMA Error Bits
  [18:16] TEB ro — Tx DMA Error Bits
  [15] NIS — Normal Interrupt Summary
  [14] AIS — Abnormal Interrupt Summary
  [13] CDE — Context Descriptor Error
  [12] FBE — Fatal Bus Error
  [11] ERI — Early Receive Interrupt
  [10] ETI — Early Transmit Interrupt
  [9] RWT — Receive Watchdog Timeout
  [8] RPS — Receive Process Stopped
  [7] RBU — Receive Buffer Unavailable
  [6] RI — Receive Interrupt
  [2] TBU — Transmit Buffer Unavailable
  [1] TPS — Transmit Process Stopped
  [0] TI — Transmit Interrupt
0x1164 ETH_DMAC0MFCR — Channel 0 missed frame count register
  [15] MFCO — Overflow status of the MFC Counter
  [10:0] MFC — Dropped Packet Counters
0x1188 ETH_DMAC1RXCR — Channel 1 receive control register
  fields as ETH_DMAC0RXCR
0x1198 ETH_DMAC1RXDLHAR — Channel 1 R1 descriptor list high address register
  [7:0] RDESHA — Start of Receive List
0x119C ETH_DMAC1RXDLAR — Channel 1 R1 descriptor list address register
  [31:0] RDESLA — Start of Receive List
0x11A8 ETH_DMAC1RXDTPR — Channel 1 R1 descriptor tail pointer register
  [31:0] RDT — Receive Descriptor Tail Pointer
0x11B0 ETH_DMAC1RXRLR — Channel 1 R1 descriptor ring length register
  fields as ETH_DMAC0RXRLR
0x11B8 ETH_DMAC1RXIWTR — Channel 1 R1 interrupt watchdog timer register
  fields as ETH_DMAC0RXIWTR
0x11CC ETH_DMAC1CARXDR ro — Channel 1 current application receive descriptor register
  [31:0] CURRDESAPTR — Application Receive Descriptor Address Pointer
0x11D8 ETH_DMAC1CARXBHR ro — Channel 1 current application receive buffer high register
  [7:0] CURRBUFAPTRH — Application Receive Buffer Address Pointer
0x11DC ETH_DMAC1CARXBR ro — Channel 1 current application receive buffer register
  [31:0] CURRBUFAPTR — Application Receive Buffer Address Pointer
0x11E4 ETH_DMAC1MFCR — Channel 1 missed frame count register
  fields as ETH_DMAC0MFCR
